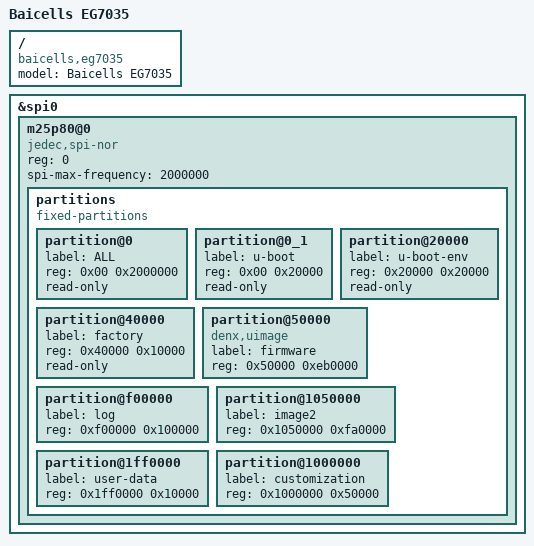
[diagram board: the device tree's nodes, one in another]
// SPDX-License-Identifier: GPL-2.0-or-later OR MIT

#include "mt7620a.dtsi"

#include <dt-bindings/gpio/gpio.h>
#include <dt-bindings/input/input.h>
#include <dt-bindings/leds/common.h>

/ {
	compatible = "baicells,eg7035", "ralink,mt7620a-soc";
	model = "Baicells EG7035";

};

// TODO leds
// TODO keys, keys polled
// TODO gpio

	// keys {
	// 	compatible = "gpio-keys-polled";
	// 	poll-interval = <20>;

	// 	reset {
	// 		label = "reset";
	// 		gpios = <0x11 0x18 0x01>;
	// 		linux,code = <0x198>;
	// 	};

	// };

&spi0 {
	status = "okay";

	m25p80@0 {
		compatible = "jedec,spi-nor";
		reg = <0>;
		spi-max-frequency = <2000000>;

		partitions {
			compatible = "fixed-partitions";
			#address-cells = <1>;
			#size-cells = <1>;

			partition@0 {
				label = "ALL";
				reg = <0x00 0x2000000>;
				read-only;
			};

			partition@0_1 {
				label = "u-boot";
				reg = <0x00 0x20000>;
				read-only;
			};

			partition@20000 {
				label = "u-boot-env";
				reg = <0x20000 0x20000>;
				read-only;
			};

			partition@40000 {
				// TODO is MAC in here? IMEI? What else?
				label = "factory";
				reg = <0x40000 0x10000>;
				read-only;
			};

			partition@50000 {
				compatible = "denx,uimage";
				label = "firmware";
				reg = <0x50000 0xeb0000>;
			};

			partition@f00000 {
				label = "log";
				reg = <0xf00000 0x100000>;
			};

			partition@1050000 {
				label = "image2";
				reg = <0x1050000 0xfa0000>;
			};

			partition@1ff0000 {
				label = "user-data";
				reg = <0x1ff0000 0x10000>;
			};

			partition@1000000 {
				label = "customization";
				reg = <0x1000000 0x50000>;
			};
		};
	};
};
